AUTOSAR XML (schema 4-0-3)
package /ComponentTypes
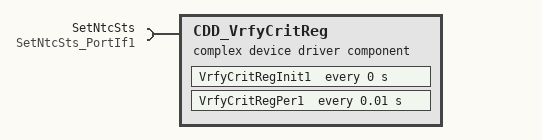
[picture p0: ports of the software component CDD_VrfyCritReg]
  complex device driver sw component type CDD_VrfyCritReg
    require port SetNtcSts: required-interface=SetNtcSts_PortIf1
    behavior CDD_VrfyCritReg_InternalBehavior
      ar-typed-per-instance-memorys:
        6 x data, all with sw-calibration-access=READ-ONLY, type=uint32:
          dVrfyCritRegCritRegActVal
          dVrfyCritRegCritRegAdr
          dVrfyCritRegCritRegDesVal
          dVrfyCritRegSysCritRegActVal
          dVrfyCritRegSysCritRegAdr
          dVrfyCritRegSysCritRegDesVal
      timing event VrfyCritRegInit1_InitEvent: start-on-event=VrfyCritRegInit1, period=0
      timing event TMT_VrfyCritRegPer1: start-on-event=VrfyCritRegPer1, period=0.01
      runnable VrfyCritRegInit1
        sync call SC_SetNtcSts_Oper: operation=SetNtcSts.Oper, timeout=0
      runnable VrfyCritRegPer1
        sync call SC_SetNtcSts_Oper: operation=SetNtcSts.Oper, timeout=0
  swc implementation CDD_VrfyCritReg_Implementation: behavior=CDD_VrfyCritReg_InternalBehavior
    code-descriptors:
      code Default: artifact-descriptors=autosar-engineering-object={short-label=Default, category=SWSRC}
